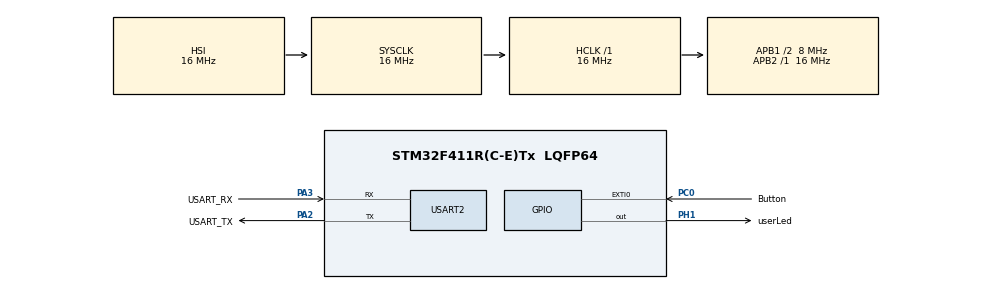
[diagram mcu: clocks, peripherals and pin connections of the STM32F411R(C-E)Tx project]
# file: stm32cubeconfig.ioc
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Mcu.Family=STM32F4
Mcu.Name=STM32F411R(C-E)Tx
Mcu.Package=LQFP64
NVIC.PriorityGroup=NVIC_PRIORITYGROUP_0
PA13.GPIO_Label=TMS
PA13.Mode=Serial_Wire
PA13.Signal=SYS_JTMS-SWDIO
PA14.GPIO_Label=TCK
PA14.Mode=Serial_Wire
PA14.Signal=SYS_JTCK-SWCLK
PA2.GPIO_Label=USART_TX
PA2.Mode=Asynchronous
PA2.Signal=USART2_TX
PA3.GPIO_Label=USART_RX
PA3.Mode=Asynchronous
PA3.Signal=USART2_RX
PB3.GPIO_Label=SWO
PB3.Signal=SYS_JTDO-SWO
PC0.GPIO_Label=Button
PC0.Signal=GPXTI0
PH1\ -\ OSC_OUT.GPIO_Label=userLed
PH1\ -\ OSC_OUT.PinState=GPIO_PIN_SET
PH1\ -\ OSC_OUT.Signal=GPIO_Output
ProjectManager.HeapSize=0x200
ProjectManager.StackSize=0x400
ProjectManager.TargetToolchain=STM32CubeIDE
RCC.48MHZClocksFreq_Value=84000000
RCC.AHBFreq_Value=16000000
RCC.APB1CLKDivider=RCC_HCLK_DIV2
RCC.APB1Freq_Value=8000000
RCC.APB1TimFreq_Value=16000000
RCC.APB2Freq_Value=16000000
RCC.APB2TimFreq_Value=16000000
RCC.CortexFreq_Value=16000000
RCC.FLatency-AdvancedSettings=FLASH_LATENCY_0
RCC.HCLKFreq_Value=16000000
RCC.HSE_VALUE=8000000
RCC.HSI_VALUE=16000000
RCC.LSE_VALUE=32768
RCC.PLLN=336
RCC.PLLP=RCC_PLLP_DIV4
RCC.SYSCLKFreq_VALUE=16000000
RCC.VCOOutputFreq_Value=336000000
TIM2.Period=256-1
TIM2.Prescaler=16000-1
USART2.VirtualMode=VM_ASYNC
VP_TIM2_VS_ClockSourceINT.Mode=Internal
board=NUCLEO-F411RE

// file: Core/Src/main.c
/* USER CODE BEGIN Header */
/**
  ******************************************************************************
  * @file           : main.c
  * @brief          : Main program body
  ******************************************************************************
  * @attention
  *
  * Copyright (c) 2025 STMicroelectronics.
  * All rights reserved.
  *
  * This software is licensed under terms that can be found in the LICENSE file
  * in the root directory of this software component.
  * If no LICENSE file comes with this software, it is provided AS-IS.
  *
  ******************************************************************************
  */
/* USER CODE END Header */
#include "main.h"

/* USER CODE BEGIN Includes */
#include "arm_math.h"
/* USER CODE END Includes */

/* USER CODE BEGIN PD */
#define FFT_Length  1024
/* USER CODE END PD */

TIM_HandleTypeDef htim2;

UART_HandleTypeDef huart2;

/* USER CODE BEGIN PV */
float32_t FFT_Input_Q15_f[50];
float32_t aFFT_Input_Q15[50];
/* USER CODE END PV */

void SystemClock_Config(void);
static void MX_GPIO_Init(void);
static void MX_USART2_UART_Init(void);
static void MX_TIM2_Init(void);

int main(void)
{

  /* USER CODE BEGIN 1 */
arm_float_to_q15((float32_t *)&FFT_Input_Q15_f[0], (q15_t *)&aFFT_Input_Q15[0], FFT_Length*2);
  /* USER CODE END 1 */

  /* MCU Configuration--------------------------------------------------------*/

  /* Reset of all peripherals, Initializes the Flash interface and the Systick. */
  HAL_Init();

  /* Configure the system clock */
  SystemClock_Config();

  /* Initialize all configured peripherals */
  MX_GPIO_Init();
  MX_USART2_UART_Init();
  MX_TIM2_Init();

  /* Infinite loop */
  while (1)
  {

  }
}

void SystemClock_Config(void)
{
  RCC_OscInitTypeDef RCC_OscInitStruct = {0};
  RCC_ClkInitTypeDef RCC_ClkInitStruct = {0};

  /** Configure the main internal regulator output voltage
  */
  __HAL_RCC_PWR_CLK_ENABLE();
  __HAL_PWR_VOLTAGESCALING_CONFIG(PWR_REGULATOR_VOLTAGE_SCALE1);

  /** Initializes the RCC Oscillators according to the specified parameters
  * in the RCC_OscInitTypeDef structure.
  */
  RCC_OscInitStruct.OscillatorType = RCC_OSCILLATORTYPE_HSI;
  RCC_OscInitStruct.HSIState = RCC_HSI_ON;
  RCC_OscInitStruct.HSICalibrationValue = RCC_HSICALIBRATION_DEFAULT;
  RCC_OscInitStruct.PLL.PLLState = RCC_PLL_NONE;
  if (HAL_RCC_OscConfig(&RCC_OscInitStruct) != HAL_OK)
  {
    Error_Handler();
  }

  /** Initializes the CPU, AHB and APB buses clocks
  */
  RCC_ClkInitStruct.ClockType = RCC_CLOCKTYPE_HCLK|RCC_CLOCKTYPE_SYSCLK
                              |RCC_CLOCKTYPE_PCLK1|RCC_CLOCKTYPE_PCLK2;
  RCC_ClkInitStruct.SYSCLKSource = RCC_SYSCLKSOURCE_HSI;
  RCC_ClkInitStruct.AHBCLKDivider = RCC_SYSCLK_DIV1;
  RCC_ClkInitStruct.APB1CLKDivider = RCC_HCLK_DIV2;
  RCC_ClkInitStruct.APB2CLKDivider = RCC_HCLK_DIV1;

  if (HAL_RCC_ClockConfig(&RCC_ClkInitStruct, FLASH_LATENCY_0) != HAL_OK)
  {
    Error_Handler();
  }
}

static void MX_TIM2_Init(void)
{

  TIM_ClockConfigTypeDef sClockSourceConfig = {0};
  TIM_MasterConfigTypeDef sMasterConfig = {0};

  htim2.Instance = TIM2;
  htim2.Init.Prescaler = 16000-1;
  htim2.Init.CounterMode = TIM_COUNTERMODE_UP;
  htim2.Init.Period = 256-1;
  htim2.Init.ClockDivision = TIM_CLOCKDIVISION_DIV1;
  htim2.Init.AutoReloadPreload = TIM_AUTORELOAD_PRELOAD_DISABLE;
  if (HAL_TIM_Base_Init(&htim2) != HAL_OK)
  {
    Error_Handler();
  }
  sClockSourceConfig.ClockSource = TIM_CLOCKSOURCE_INTERNAL;
  if (HAL_TIM_ConfigClockSource(&htim2, &sClockSourceConfig) != HAL_OK)
  {
    Error_Handler();
  }
  sMasterConfig.MasterOutputTrigger = TIM_TRGO_RESET;
  sMasterConfig.MasterSlaveMode = TIM_MASTERSLAVEMODE_DISABLE;
  if (HAL_TIMEx_MasterConfigSynchronization(&htim2, &sMasterConfig) != HAL_OK)
  {
    Error_Handler();
  }

}

static void MX_USART2_UART_Init(void)
{

  huart2.Instance = USART2;
  huart2.Init.BaudRate = 115200;
  huart2.Init.WordLength = UART_WORDLENGTH_8B;
  huart2.Init.StopBits = UART_STOPBITS_1;
  huart2.Init.Parity = UART_PARITY_NONE;
  huart2.Init.Mode = UART_MODE_TX_RX;
  huart2.Init.HwFlowCtl = UART_HWCONTROL_NONE;
  huart2.Init.OverSampling = UART_OVERSAMPLING_16;
  if (HAL_UART_Init(&huart2) != HAL_OK)
  {
    Error_Handler();
  }

}

static void MX_GPIO_Init(void)
{
  GPIO_InitTypeDef GPIO_InitStruct = {0};

  /* GPIO Ports Clock Enable */
  __HAL_RCC_GPIOH_CLK_ENABLE();
  __HAL_RCC_GPIOC_CLK_ENABLE();
  __HAL_RCC_GPIOA_CLK_ENABLE();
  __HAL_RCC_GPIOB_CLK_ENABLE();

  /*Configure GPIO pin Output Level */
  HAL_GPIO_WritePin(userLed_GPIO_Port, userLed_Pin, GPIO_PIN_SET);

  /*Configure GPIO pin : userLed_Pin */
  GPIO_InitStruct.Pin = userLed_Pin;
  GPIO_InitStruct.Mode = GPIO_MODE_OUTPUT_PP;
  GPIO_InitStruct.Pull = GPIO_NOPULL;
  GPIO_InitStruct.Speed = GPIO_SPEED_FREQ_LOW;
  HAL_GPIO_Init(userLed_GPIO_Port, &GPIO_InitStruct);

  /*Configure GPIO pin : Button_Pin */
  GPIO_InitStruct.Pin = Button_Pin;
  GPIO_InitStruct.Mode = GPIO_MODE_IT_RISING;
  GPIO_InitStruct.Pull = GPIO_NOPULL;
  HAL_GPIO_Init(Button_GPIO_Port, &GPIO_InitStruct);

}

void Error_Handler(void)
{
  __disable_irq();
  while (1)
  {
  }
}
